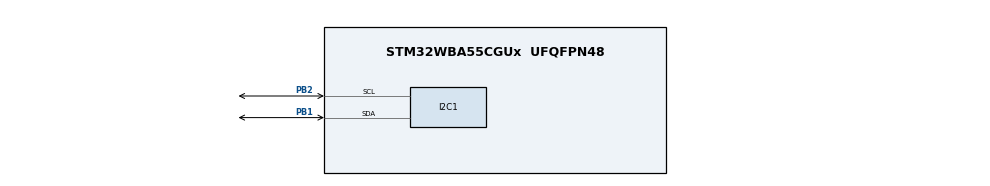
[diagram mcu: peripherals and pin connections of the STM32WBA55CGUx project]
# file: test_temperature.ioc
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CORTEX_M33_NS.userName=CORTEX_M33
I2C1.Timing=0x00707CBB
Mcu.Family=STM32WBA
Mcu.Name=STM32WBA55CGUx
Mcu.Package=UFQFPN48
NUCLEO-WBA55CG.BUTTON=1
NUCLEO-WBA55CG.BUTTON2=1
NUCLEO-WBA55CG.BUTTON3=1
NUCLEO-WBA55CG.LD1=true
NUCLEO-WBA55CG.LD2=true
NUCLEO-WBA55CG.LD3=true
NUCLEO-WBA55CG.VCP=true
NVIC.I2C1_ER_IRQn=true\:9\:0\:true\:false\:true\:true\:true\:true
NVIC.I2C1_EV_IRQn=true\:10\:0\:true\:false\:true\:true\:true\:true
NVIC.PriorityGroup=NVIC_PRIORITYGROUP_4
OSC_IN.GPIO_Label=RCC_OSC_IN
OSC_IN.Mode=HSE-External-Oscillator
OSC_IN.Signal=RCC_OSC_IN
OSC_OUT.GPIO_Label=RCC_OSC_OUT
OSC_OUT.Mode=HSE-External-Oscillator
OSC_OUT.Signal=RCC_OSC_OUT
PA13\ (JTMS/SWDIO).GPIO_Label=DEBUG_JTMS-SWDIO
PA13\ (JTMS/SWDIO).Mode=Serial_Wire
PA13\ (JTMS/SWDIO).Signal=DEBUG_JTMS-SWDIO
PA14\ (JTCK/SWCLK).GPIO_Label=DEBUG_JTCK-SWCLK
PA14\ (JTCK/SWCLK).Mode=Serial_Wire
PA14\ (JTCK/SWCLK).Signal=DEBUG_JTCK-SWCLK
PA8.Signal=USART1_RX
PB1.GPIO_Pu=GPIO_PULLUP
PB1.Mode=I2C
PB1.Signal=I2C1_SDA
PB12.Signal=USART1_TX
PB2.GPIO_Pu=GPIO_PULLUP
PB2.Mode=I2C
PB2.Signal=I2C1_SCL
PC14-OSC32_IN.GPIO_Label=RCC_OSC32_IN
PC14-OSC32_IN.Mode=LSE-External-Oscillator
PC14-OSC32_IN.Signal=RCC_OSC32_IN
PC15-OSC32_OUT.GPIO_Label=RCC_OSC32_OUT
PC15-OSC32_OUT.Mode=LSE-External-Oscillator
PC15-OSC32_OUT.Signal=RCC_OSC32_OUT
ProjectManager.HeapSize=0x200
ProjectManager.StackSize=0x400
ProjectManager.TargetToolchain=STM32CubeIDE
RCC.ADCFreq_Value=32000000
RCC.AHBFreq_Value=32000000
RCC.APB1Freq_Value=32000000
RCC.APB1TimFreq_Value=32000000
RCC.APB2Freq_Value=32000000
RCC.APB2TimFreq_Value=32000000
RCC.CortexFreq_Value=4000000
RCC.HCLKFreq_Value=32000000
RCC.HSE_VALUE=32000000
RCC.HSI_VALUE=16000000
RCC.LSI1_VALUE=32000
RCC.LSI2_VALUE=32000
RCC.PLLFRACN=0
RCC.PLLM=2
RCC.PLLN=8
RCC.PLLSourceVirtual=RCC_PLLSOURCE_HSE
RCC.PWR_Regulator_Voltage_Scale=PWR_REGULATOR_VOLTAGE_SCALE1
RCC.RTCClockSelection=RCC_RTCCLKSOURCE_LSE
RCC.SYSCLKFreq_VALUE=32000000
RCC.SYSCLKSourceVirtual=RCC_SYSCLKSOURCE_HSE
RCC.VCOOutputFreq_Value=128000000
VP_CORTEX_M33_NS_VS_Hclk.Mode=Hclk_Mode
VP_ICACHE_VS_ICACHE.Mode=DirectMappedCache
VP_MEMORYMAP_VS_MEMORYMAP.Mode=CurAppReg
VP_NUCLEO-WBA55CG_VS_BSP_COMMON.Mode=COMMON
VP_PWR_VS_SECSignals.Mode=Security/Privilege
board=NUCLEO-WBA55CG

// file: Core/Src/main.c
/* USER CODE BEGIN Header */
/**
  ******************************************************************************
  * @file           : main.c
  * @brief          : Main program body
  ******************************************************************************
  * @attention
  *
  * Copyright (c) 2025 STMicroelectronics.
  * All rights reserved.
  *
  * This software is licensed under terms that can be found in the LICENSE file
  * in the root directory of this software component.
  * If no LICENSE file comes with this software, it is provided AS-IS.
  *
  ******************************************************************************
  */
/* USER CODE END Header */
#include "main.h"

/* USER CODE BEGIN Includes */
#include "i2c_util.h"
#include "sht40.h"
/* USER CODE END Includes */

COM_InitTypeDef BspCOMInit;

/* USER CODE BEGIN PV */
i2c_t i2c_sht40;
/* USER CODE END PV */

void SystemClock_Config(void);
static void MX_GPIO_Init(void);
static void MX_I2C1_Init(void);
static void MX_ICACHE_Init(void);

int main(void)
{

  /* MCU Configuration--------------------------------------------------------*/

  /* Reset of all peripherals, Initializes the Flash interface and the Systick. */
  HAL_Init();

  /* Enable PWR clock interface */

  LL_AHB4_GRP1_EnableClock(LL_AHB4_GRP1_PERIPH_PWR);

  /* Configure the system clock */
  SystemClock_Config();

  /* Initialize all configured peripherals */
  MX_GPIO_Init();
  MX_I2C1_Init();
  MX_ICACHE_Init();

  /* Initialize leds */
  BSP_LED_Init(LED_BLUE);
  BSP_LED_Init(LED_GREEN);
  BSP_LED_Init(LED_RED);

  /* Initialize USER push-button, will be used to trigger an interrupt each time it's pressed.*/
  BSP_PB_Init(B1, BUTTON_MODE_EXTI);
  BSP_PB_Init(B2, BUTTON_MODE_EXTI);
  BSP_PB_Init(B3, BUTTON_MODE_EXTI);

  /* Initialize COM1 port (115200, 8 bits (7-bit data + 1 stop bit), no parity */
  BspCOMInit.BaudRate   = 115200;
  BspCOMInit.WordLength = COM_WORDLENGTH_8B;
  BspCOMInit.StopBits   = COM_STOPBITS_1;
  BspCOMInit.Parity     = COM_PARITY_NONE;
  BspCOMInit.HwFlowCtl  = COM_HWCONTROL_NONE;
  if (BSP_COM_Init(COM1, &BspCOMInit) != BSP_ERROR_NONE)
  {
    Error_Handler();
  }

  /* Infinite loop */
  /* USER CODE BEGIN WHILE */
  printf( "Start\n");

  i2c_init(&i2c_sht40, I2C1);
  HAL_Delay(10);
  sht40_reset(&i2c_sht40);
  HAL_Delay(10);

  uint32_t last_tick = 0;
  while (1)
  {
	uint32_t current_tick = HAL_GetTick();
	if ((current_tick - last_tick) >= 5000) {
		last_tick = current_tick;
		BSP_LED_On(LD1);
		//printf( "Write\n");
		sht40_start_measurement(&i2c_sht40, I2C_SHT40_CMD_MEAS_HI_ACC);
		BSP_LED_Off(LD1);
	}
	if ((i2c_sht40.state == I2C_STATE_WRITING) && (i2c_sht40.timeout == 0)) {
		BSP_LED_On(LD2);
		//printf( "Read\n");
		i2c_sht40.state = I2C_STATE_READING;
		LL_I2C_HandleTransfer(i2c_sht40.i2c, (I2C_SHT40_ADDR << 1), LL_I2C_ADDRSLAVE_7BIT, 6, LL_I2C_MODE_AUTOEND, LL_I2C_GENERATE_START_READ);
		BSP_LED_Off(LD2);
	}
	if (i2c_sht40.done == 1) {
		i2c_sht40.done = 0;
		//printf("Done\n");

		uint16_t temp_raw = ((uint16_t)i2c_sht40.rxbuf[0] << 8) | (uint16_t)i2c_sht40.rxbuf[1];
		uint16_t hum_raw = ((uint16_t)i2c_sht40.rxbuf[3] << 8) | (uint16_t)i2c_sht40.rxbuf[4];
		// TODO: CRC check

		uint32_t temperature = ((21875 * (int32_t)temp_raw) >> 13) - 45000;
		uint32_t humidity = ((15625 * (int32_t)hum_raw) >> 13) - 6000;

		printf("Temperature: %li   ", temperature);
		printf("Humidity: %li\n", humidity);
	}
    /* USER CODE END WHILE */

  }
}

void SystemClock_Config(void)
{
  LL_FLASH_SetLatency(LL_FLASH_LATENCY_0);
  while(LL_FLASH_GetLatency()!= LL_FLASH_LATENCY_0)
  {
  }

  LL_PWR_SetRegulVoltageScaling(LL_PWR_REGU_VOLTAGE_SCALE1);
  LL_RCC_HSE_Enable();

   /* Wait till HSE is ready */
  while(LL_RCC_HSE_IsReady() != 1)
  {
  }

  LL_RCC_SetSysClkSource(LL_RCC_SYS_CLKSOURCE_HSE);

   /* Wait till System clock is ready */
  while(LL_RCC_GetSysClkSource() != LL_RCC_SYS_CLKSOURCE_STATUS_HSE)
  {
  }

  LL_RCC_SetAHBPrescaler(LL_RCC_SYSCLK_DIV_1);
  LL_RCC_SetAHB5Divider(LL_RCC_AHB5_DIVIDER_1);
  LL_RCC_SetAPB1Prescaler(LL_RCC_APB1_DIV_1);
  LL_RCC_SetAPB2Prescaler(LL_RCC_APB2_DIV_1);
  LL_RCC_SetAPB7Prescaler(LL_RCC_APB7_DIV_1);
  LL_SetSystemCoreClock(32000000);

   /* Update the time base */
  if (HAL_InitTick (TICK_INT_PRIORITY) != HAL_OK)
  {
    Error_Handler();
  }
}

static void MX_I2C1_Init(void)
{

  LL_I2C_InitTypeDef I2C_InitStruct = {0};

  LL_GPIO_InitTypeDef GPIO_InitStruct = {0};

  LL_RCC_SetI2CClockSource(LL_RCC_I2C1_CLKSOURCE_PCLK1);

  LL_AHB2_GRP1_EnableClock(LL_AHB2_GRP1_PERIPH_GPIOB);
  /**I2C1 GPIO Configuration
  PB2   ------> I2C1_SCL
  PB1   ------> I2C1_SDA
  */
  GPIO_InitStruct.Pin = LL_GPIO_PIN_2|LL_GPIO_PIN_1;
  GPIO_InitStruct.Mode = LL_GPIO_MODE_ALTERNATE;
  GPIO_InitStruct.Speed = LL_GPIO_SPEED_FREQ_LOW;
  GPIO_InitStruct.OutputType = LL_GPIO_OUTPUT_OPENDRAIN;
  GPIO_InitStruct.Pull = LL_GPIO_PULL_UP;
  GPIO_InitStruct.Alternate = LL_GPIO_AF_4;
  LL_GPIO_Init(GPIOB, &GPIO_InitStruct);

  /* Peripheral clock enable */
  LL_APB1_GRP1_EnableClock(LL_APB1_GRP1_PERIPH_I2C1);

  /* I2C1 interrupt Init */
  NVIC_SetPriority(I2C1_EV_IRQn, NVIC_EncodePriority(NVIC_GetPriorityGrouping(),10, 0));
  NVIC_EnableIRQ(I2C1_EV_IRQn);
  NVIC_SetPriority(I2C1_ER_IRQn, NVIC_EncodePriority(NVIC_GetPriorityGrouping(),9, 0));
  NVIC_EnableIRQ(I2C1_ER_IRQn);

  /** I2C Initialization
  */
  LL_I2C_EnableAutoEndMode(I2C1);
  LL_I2C_DisableOwnAddress2(I2C1);
  LL_I2C_DisableGeneralCall(I2C1);
  LL_I2C_EnableClockStretching(I2C1);
  I2C_InitStruct.PeripheralMode = LL_I2C_MODE_I2C;
  I2C_InitStruct.Timing = 0x00300F38;
  I2C_InitStruct.AnalogFilter = LL_I2C_ANALOGFILTER_ENABLE;
  I2C_InitStruct.DigitalFilter = 0;
  I2C_InitStruct.OwnAddress1 = 0;
  I2C_InitStruct.TypeAcknowledge = LL_I2C_ACK;
  I2C_InitStruct.OwnAddrSize = LL_I2C_OWNADDRESS1_7BIT;
  LL_I2C_Init(I2C1, &I2C_InitStruct);
  LL_I2C_SetOwnAddress2(I2C1, 0, LL_I2C_OWNADDRESS2_NOMASK);

}

static void MX_ICACHE_Init(void)
{

  /** Enable instruction cache in 1-way (direct mapped cache)
  */
  LL_ICACHE_SetMode(LL_ICACHE_1WAY);
  LL_ICACHE_Enable();

}

static void MX_GPIO_Init(void)
{

  /* GPIO Ports Clock Enable */
  LL_AHB2_GRP1_EnableClock(LL_AHB2_GRP1_PERIPH_GPIOC);
  LL_AHB2_GRP1_EnableClock(LL_AHB2_GRP1_PERIPH_GPIOA);
  LL_AHB2_GRP1_EnableClock(LL_AHB2_GRP1_PERIPH_GPIOB);

}

void Error_Handler(void)
{
  __disable_irq();
  while (1)
  {
  }
}
